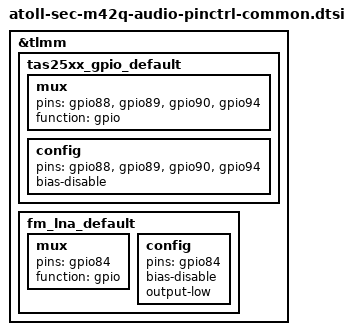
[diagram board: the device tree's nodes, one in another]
/* Copyright (c) 2019, The Linux Foundation. All rights reserved.
 *
 * This program is free software; you can redistribute it and/or modify
 * it under the terms of the GNU General Public License version 2 and
 * only version 2 as published by the Free Software Foundation.
 *
 * This program is distributed in the hope that it will be useful,
 * but WITHOUT ANY WARRANTY; without even the implied warranty of
 * MERCHANTABILITY or FITNESS FOR A PARTICULAR PURPOSE.  See the
 * GNU General Public License for more details.
 */

&tlmm {
	tas25xx_gpio_default: tas25xx_gpio_default {
		mux {
			pins = "gpio88", "gpio89", "gpio90", "gpio94";
			function = "gpio";
		};
		config {
			pins = "gpio88", "gpio89", "gpio90", "gpio94";
			bias-disable; /* No PULL */
		};
	};

	fm_lna_default: fm_lna_default {
		mux {
			pins = "gpio84";
			function = "gpio";
		};
		config {
			pins = "gpio84";
			bias-disable; /* No PULL */
			output-low;
		};
	};
};
